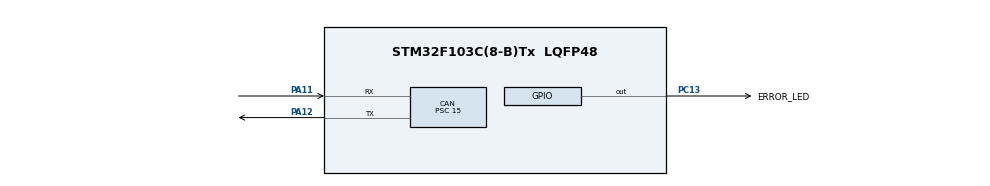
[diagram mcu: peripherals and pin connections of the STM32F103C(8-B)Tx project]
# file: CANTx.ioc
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CAN.BS1=CAN_BS1_2TQ
CAN.BS2=CAN_BS2_3TQ
CAN.CalculateBaudRate=88888
CAN.CalculateTimeBit=11250
CAN.CalculateTimeQuantum=1875.0
CAN.Prescaler=15
CAN.SJW=CAN_SJW_2TQ
Mcu.Family=STM32F1
Mcu.Name=STM32F103C(8-B)Tx
Mcu.Package=LQFP48
NVIC.PriorityGroup=NVIC_PRIORITYGROUP_4
PA11.Mode=CAN_Activate
PA11.Signal=CAN_RX
PA12.Mode=CAN_Activate
PA12.Signal=CAN_TX
PC13-TAMPER-RTC.GPIO_Label=ERROR_LED
PC13-TAMPER-RTC.Signal=GPIO_Output
ProjectManager.HeapSize=0x200
ProjectManager.StackSize=0x400
ProjectManager.TargetToolchain=STM32CubeIDE
RCC.APB1Freq_Value=8000000
RCC.APB2Freq_Value=8000000
board=custom

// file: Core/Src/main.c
/* USER CODE BEGIN Header */
/**
  ******************************************************************************
  * @file           : main.c
  * @brief          : Main program body
  ******************************************************************************
  * @attention
  *
  * Copyright (c) 2023 STMicroelectronics.
  * All rights reserved.
  *
  * This software is licensed under terms that can be found in the LICENSE file
  * in the root directory of this software component.
  * If no LICENSE file comes with this software, it is provided AS-IS.
  *
  ******************************************************************************
  */
/* USER CODE END Header */
#include "main.h"

CAN_HandleTypeDef hcan;

/* USER CODE BEGIN PV */
CAN_TxHeaderTypeDef TxHeader;

uint8_t TxData[8];

uint32_t TxMailbox;

/* USER CODE END PV */

void SystemClock_Config(void);
static void MX_GPIO_Init(void);
static void MX_CAN_Init(void);

int main(void)
{

  /* MCU Configuration--------------------------------------------------------*/

  /* Reset of all peripherals, Initializes the Flash interface and the Systick. */
  HAL_Init();

  /* Configure the system clock */
  SystemClock_Config();

  /* Initialize all configured peripherals */
  MX_GPIO_Init();
  MX_CAN_Init();
  /* USER CODE BEGIN 2 */
	HAL_CAN_Start(&hcan);

  /* USER CODE END 2 */

  /* Infinite loop */
  /* USER CODE BEGIN WHILE */
	TxHeader.IDE = CAN_ID_STD;
	TxHeader.StdId = 0x103;
	TxHeader.RTR = CAN_RTR_DATA;
	TxHeader.DLC = 1;

	TxData[0] = 0x50;
	// TxData[1] = 0xAA;

	while (1)
	{
    /* USER CODE END WHILE */

    /* USER CODE BEGIN 3 */
		HAL_CAN_AddTxMessage(&hcan, &TxHeader, TxData, &TxMailbox);
		HAL_Delay(10);
	}
  /* USER CODE END 3 */
}

void SystemClock_Config(void)
{
  RCC_OscInitTypeDef RCC_OscInitStruct = {0};
  RCC_ClkInitTypeDef RCC_ClkInitStruct = {0};

  /** Initializes the RCC Oscillators according to the specified parameters
  * in the RCC_OscInitTypeDef structure.
  */
  RCC_OscInitStruct.OscillatorType = RCC_OSCILLATORTYPE_HSI;
  RCC_OscInitStruct.HSIState = RCC_HSI_ON;
  RCC_OscInitStruct.HSICalibrationValue = RCC_HSICALIBRATION_DEFAULT;
  RCC_OscInitStruct.PLL.PLLState = RCC_PLL_NONE;
  if (HAL_RCC_OscConfig(&RCC_OscInitStruct) != HAL_OK)
  {
    Error_Handler();
  }

  /** Initializes the CPU, AHB and APB buses clocks
  */
  RCC_ClkInitStruct.ClockType = RCC_CLOCKTYPE_HCLK|RCC_CLOCKTYPE_SYSCLK
                              |RCC_CLOCKTYPE_PCLK1|RCC_CLOCKTYPE_PCLK2;
  RCC_ClkInitStruct.SYSCLKSource = RCC_SYSCLKSOURCE_HSI;
  RCC_ClkInitStruct.AHBCLKDivider = RCC_SYSCLK_DIV1;
  RCC_ClkInitStruct.APB1CLKDivider = RCC_HCLK_DIV1;
  RCC_ClkInitStruct.APB2CLKDivider = RCC_HCLK_DIV1;

  if (HAL_RCC_ClockConfig(&RCC_ClkInitStruct, FLASH_LATENCY_0) != HAL_OK)
  {
    Error_Handler();
  }
}

static void MX_CAN_Init(void)
{

  hcan.Instance = CAN1;
  hcan.Init.Prescaler = 15;
  hcan.Init.Mode = CAN_MODE_NORMAL;
  hcan.Init.SyncJumpWidth = CAN_SJW_2TQ;
  hcan.Init.TimeSeg1 = CAN_BS1_2TQ;
  hcan.Init.TimeSeg2 = CAN_BS2_3TQ;
  hcan.Init.TimeTriggeredMode = DISABLE;
  hcan.Init.AutoBusOff = DISABLE;
  hcan.Init.AutoWakeUp = DISABLE;
  hcan.Init.AutoRetransmission = DISABLE;
  hcan.Init.ReceiveFifoLocked = DISABLE;
  hcan.Init.TransmitFifoPriority = DISABLE;
  if (HAL_CAN_Init(&hcan) != HAL_OK)
  {
    Error_Handler();
  }

}

static void MX_GPIO_Init(void)
{
  GPIO_InitTypeDef GPIO_InitStruct = {0};

  /* GPIO Ports Clock Enable */
  __HAL_RCC_GPIOC_CLK_ENABLE();
  __HAL_RCC_GPIOA_CLK_ENABLE();

  /*Configure GPIO pin Output Level */
  HAL_GPIO_WritePin(ERROR_LED_GPIO_Port, ERROR_LED_Pin, GPIO_PIN_RESET);

  /*Configure GPIO pin : ERROR_LED_Pin */
  GPIO_InitStruct.Pin = ERROR_LED_Pin;
  GPIO_InitStruct.Mode = GPIO_MODE_OUTPUT_PP;
  GPIO_InitStruct.Pull = GPIO_NOPULL;
  GPIO_InitStruct.Speed = GPIO_SPEED_FREQ_LOW;
  HAL_GPIO_Init(ERROR_LED_GPIO_Port, &GPIO_InitStruct);

}

void Error_Handler(void)
{
	__disable_irq();
	while (1)
	{
	}
}

#ifdef  USE_FULL_ASSERT
/**
  * @brief  Reports the name of the source file and the source line number
  *         where the assert_param error has occurred.
  * @param  file: pointer to the source file name
  * @param  line: assert_param error line source number
  * @retval None
  */
void assert_failed(uint8_t *file, uint32_t line)
{
  /* USER CODE BEGIN 6 */
	/* User can add his own implementation to report the file name and line number,
     ex: printf("Wrong parameters value: file %s on line %d\r\n", file,
		line) */
  /* USER CODE END 6 */
}
#endif /* USE_FULL_ASSERT */
